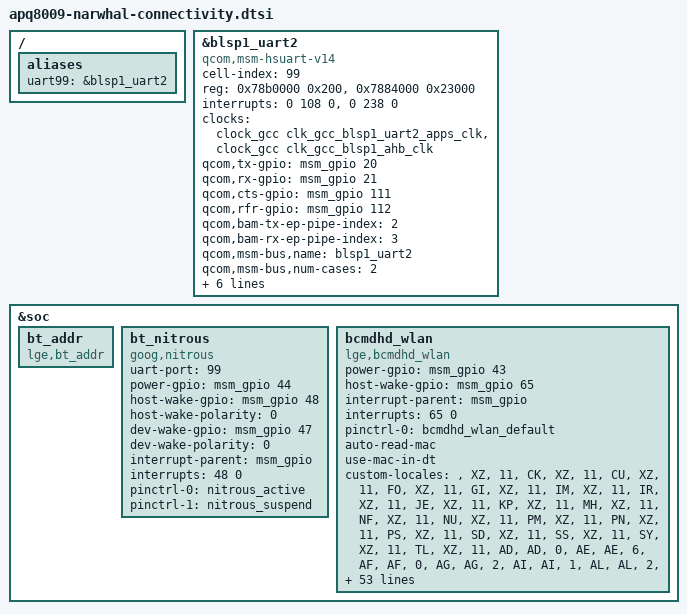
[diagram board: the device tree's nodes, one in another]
/* Copyright (c) 2014, The Linux Foundation. All rights reserved.
 *
 * This program is free software; you can redistribute it and/or modify
 * it under the terms of the GNU General Public License version 2 and
 * only version 2 as published by the Free Software Foundation.
 *
 * This program is distributed in the hope that it will be useful,
 * but WITHOUT ANY WARRANTY; without even the implied warranty of
 * MERCHANTABILITY or FITNESS FOR A PARTICULAR PURPOSE.  See the
 * GNU General Public License for more details.
 */

/ {
	aliases {
		uart99 = &blsp1_uart2;
	};
};

&blsp1_uart2 { /* BLSP1 QUP2 */
	compatible = "qcom,msm-hsuart-v14";
	cell-index = <99>;
	status = "ok";
	reg = <0x78b0000 0x200>,
	      <0x7884000 0x23000>;
	reg-names = "core_mem", "bam_mem";
	interrupts = <0 108 0>, <0 238 0>;
	interrupt-names = "core_irq", "bam_irq";
	clocks = <&clock_gcc clk_gcc_blsp1_uart2_apps_clk>,
		 <&clock_gcc clk_gcc_blsp1_ahb_clk>;
	clock-names = "core_clk", "iface_clk";
	qcom,tx-gpio = <&msm_gpio 20 0x00>;
	qcom,rx-gpio = <&msm_gpio 21 0x00>;
	qcom,cts-gpio = <&msm_gpio 111 0x00>;
	qcom,rfr-gpio = <&msm_gpio 112 0x00>;

	qcom,bam-tx-ep-pipe-index = <2>;
	qcom,bam-rx-ep-pipe-index = <3>;

	qcom,msm-bus,name = "blsp1_uart2";
	qcom,msm-bus,num-cases = <2>;
	qcom,msm-bus,num-paths = <1>;
	qcom,msm-bus,vectors-KBps = <86 512 0 0>,
				    <86 512 500 800>;
	qcom,msm-obs;
	pinctrl-names = "default", "sleep";
	pinctrl-0 = <&uart_2_active>;
	pinctrl-1 = <&uart_2_sleep>;
};

&soc {
	bt_addr: bt_addr {
		compatible = "lge,bt_addr";
	};

	bt_nitrous: bt_nitrous {
		compatible = "goog,nitrous";
		uart-port = <99>;
		power-gpio = <&msm_gpio 44 0>;
		host-wake-gpio = <&msm_gpio 48 0>;
		host-wake-polarity = <0>;
		dev-wake-gpio = <&msm_gpio 47 0>;
		dev-wake-polarity = <0>;
		interrupt-parent = <&msm_gpio>;
		interrupts = <48 0>;
		interrupt-names = "host_wake";
		pinctrl-names = "default", "sleep";
		pinctrl-0 = <&nitrous_active>;
		pinctrl-1 = <&nitrous_suspend>;
	};

	bcmdhd_wlan: bcmdhd_wlan {
		compatible = "lge,bcmdhd_wlan";
		status = "ok";
		power-gpio = <&msm_gpio 43 0>;
		host-wake-gpio = <&msm_gpio 65 0>;
		interrupt-parent = <&msm_gpio>;
		interrupts = <65 0>;
		interrupt-names = "host_wake";
		pinctrl-names = "default";
		pinctrl-0 = <&bcmdhd_wlan_default>;
		auto-read-mac;
		use-mac-in-dt;
		custom-locales =
			"",  "XZ", "11", /* unknown or empty */
			"CK", "XZ", "11", /* Cook Island (13.4.27)*/
			"CU", "XZ", "11", /* Cuba (13.4.27)*/
			"FO", "XZ", "11", /* Faroe Island (13.4.27)*/
			"GI", "XZ", "11", /* Gibraltar (13.4.27)*/
			"IM", "XZ", "11", /* Isle of Man (13.4.27)*/
			"IR", "XZ", "11", /* IRAN, (ISLAMIC REPUBLIC OF) */
			"JE", "XZ", "11", /* Jersey (13.4.27)*/
			"KP", "XZ", "11", /* North Korea (13.4.27)*/
			"MH", "XZ", "11", /* MARSHALL ISLANDS */
			"NF", "XZ", "11", /* Norfolk Island (13.4.27)*/
			"NU", "XZ", "11", /* Niue (13.4.27)*/
			"PM", "XZ", "11", /* Saint Pierre and Miquelon (13.4.27)*/
			"PN", "XZ", "11", /* Pitcairn Islands (13.4.27)*/
			"PS", "XZ", "11", /* PALESTINIAN TERRITORY, OCCUPIED */
			"SD", "XZ", "11", /* SUDAN */
			"SS", "XZ", "11", /* South_Sudan (13.4.27)*/
			"SY", "XZ", "11", /* SYRIAN ARAB REPUBLIC */
			"TL", "XZ", "11", /* TIMOR-LESTE (EAST TIMOR) */
			"AD", "AD", "0",
			"AE", "AE", "6",
			"AF", "AF", "0",
			"AG", "AG", "2",
			"AI", "AI", "1",
			"AL", "AL", "2",
			"AM", "AM", "0",
			"AN", "AN", "3",
			"AO", "AO", "0",
			"AR", "AU", "6",
			"AS", "AS", "12", /* changed 2 -> 12 */
			"AT", "AT", "4",
			"AU", "AU", "6",
			"AW", "AW", "2",
			"AZ", "AZ", "2",
			"BA", "BA", "2",
			"BB", "BB", "0",
			"BD", "BD", "2",
			"BE", "BE", "4",
			"BF", "BF", "0",
			"BG", "BG", "4",
			"BH", "BH", "4",
			"BI", "BI", "0",
			"BJ", "BJ", "0",
			"BM", "BM", "12",
			"BN", "BN", "4",
			"BO", "BO", "0",
			"BR", "BR", "15",
			"BS", "BS", "2",
			"BT", "BT", "0",
			"BW", "BW", "0",
			"BY", "BY", "3",
			"BZ", "BZ", "0",
			"CA", "US", "118",
			"CD", "CD", "0",
			"CF", "CF", "0",
			"CG", "CG", "0",
			"CH", "CH", "4",
			"CI", "CI", "0",
			"CL", "CL", "0",
			"CM", "CM", "0",
			"CN", "CN", "38",
			"CO", "CO", "17",
			"CR", "CR", "17",
			"CV", "CV", "0",
			"CX", "CX", "0",
			"CY", "CY", "4",
			"CZ", "CZ", "4",
			"DE", "DE", "7",
			"DJ", "DJ", "0",
			"DK", "DK", "4",
			"DM", "DM", "0",
			"DO", "DO", "0",
			"DZ", "DZ", "1",
			"EC", "EC", "21",
			"EE", "EE", "4",
			"EG", "EG", "0",
			"ER", "ER", "0",
			"ES", "ES", "4",
			"ET", "ET", "2",
			"FI", "FI", "4",
			"FJ", "FJ", "0",
			"FK", "FK", "0",
			"FM", "FM", "0",
			"FR", "FR", "5",
			"GA", "GA", "0",
			"GB", "GB", "6",
			"GD", "GD", "2",
			"GE", "GE", "0",
			"GF", "GF", "2",
			"GH", "GH", "0",
			"GM", "GM", "0",
			"GN", "GN", "0",
			"GP", "GP", "2",
			"GQ", "GQ", "0",
			"GR", "GR", "4",
			"GT", "GT", "1",
			"GU", "GU", "12",
			"GW", "GW", "0",
			"GY", "GY", "0",
			"HK", "HK", "2",
			"HN", "HN", "0",
			"HR", "HR", "4",
			"HT", "HT", "0",
			"HU", "HU", "4",
			"ID", "ID", "1",
			"IE", "IE", "5",
			"IL", "IL", "7",
			"IN", "IN", "3",
			"IQ", "IQ", "0",
			"IS", "IS", "4",
			"IT", "IT", "4",
			"JM", "JM", "0",
			"JO", "JO", "3",
			"JP", "JP", "58",
			"KE", "SA", "0",
			"KG", "KG", "0",
			"KH", "KH", "2",
			"KI", "KI", "0",
			"KM", "KM", "0",
			"KN", "KN", "0",
			"KR", "KR", "57",
			"KW", "KW", "5",
			"KY", "KY", "3",
			"KZ", "KZ", "0",
			"LA", "LA", "2",
			"LB", "LB", "5",
			"LC", "LC", "0",
			"LI", "LI", "4",
			"LK", "LK", "1",
			"LR", "LR", "0",
			"LS", "LS", "2",
			"LT", "LT", "4",
			"LU", "LU", "3",
			"LV", "LV", "4",
			"LY", "LY", "0",
			"MA", "MA", "2",
			"MC", "MC", "1",
			"MD", "MD", "2",
			"ME", "ME", "2",
			"MF", "MF", "0",
			"MG", "MG", "0",
			"MK", "MK", "2",
			"ML", "ML", "0",
			"MM", "MM", "0",
			"MN", "MN", "1",
			"MO", "MO", "2",
			"MP", "MP", "0",
			"MQ", "MQ", "2",
			"MR", "MR", "2",
			"MS", "MS", "0",
			"MT", "MT", "4",
			"MU", "MU", "2",
			"MV", "MV", "3",
			"MW", "MW", "1",
			"MX", "AU", "6",
			"MY", "MY", "3",
			"MZ", "MZ", "0",
			"NA", "NA", "0",
			"NC", "NC", "0",
			"NE", "NE", "0",
			"NG", "NG", "0",
			"NI", "NI", "2",
			"NL", "NL", "4",
			"NO", "NO", "4",
			"NP", "ID", "5",
			"NR", "NR", "0",
			"NZ", "NZ", "4",
			"OM", "OM", "4",
			"PA", "PA", "17",
			"PE", "PE", "20",
			"PF", "PF", "0",
			"PG", "AU", "6",
			"PH", "PH", "5",
			"PK", "PK", "0",
			"PL", "PL", "4",
			"PR", "US", "118",
			"PT", "PT", "4",
			"PW", "PW", "0",
			"PY", "PY", "2",
			"QA", "QA", "0",
			"RE", "RE", "2",
			"RKS", "KG", "0",
			"RO", "RO", "4",
			"RS", "RS", "2",
			"RU", "RU", "13",
			"RW", "RW", "0",
			"SA", "SA", "0",
			"SB", "SB", "0",
			"SC", "SC", "0",
			"SE", "SE", "4",
			"SG", "SG", "0",
			"SI", "SI", "4",
			"SK", "SK", "4",
			"SL", "SL", "0",
			"SM", "SM", "0",
			"SN", "SN", "2",
			"SO", "SO", "0",
			"SR", "SR", "0",
			"ST", "ST", "0",
			"SV", "SV", "25",
			"SZ", "SZ", "0",
			"TC", "TC", "0",
			"TD", "TD", "0",
			"TF", "TF", "0",
			"TG", "TG", "0",
			"TH", "TH", "5",
			"TJ", "TJ", "0",
			"TM", "TM", "0",
			"TN", "TN", "0",
			"TO", "TO", "0",
			"TR", "TR", "7",
			"TT", "TT", "3",
			"TV", "TV", "0",
			"TW", "TW", "1",
			"TZ", "TZ", "0",
			"UA", "UA", "8",
			"UG", "UG", "2",
			"US", "US", "118",
			"UY", "UY", "1",
			"UZ", "MA", "2",
			"VA", "VA", "2",
			"VC", "VC", "0",
			"VE", "VE", "3",
			"VG", "VG", "2",
			"VI", "US", "118",
			"VN", "VN", "4",
			"VU", "VU", "0",
			"WS", "WS", "0",
			"YE", "YE", "0",
			"YT", "YT", "2",
			"ZA", "ZA", "6",
			"ZM", "LA", "2",
			"ZW", "ZW", "0",
			"00", "XZ", "999";
	};
};
